# haltium_application register map
Vendor: Nordic Semiconductor; Series: nRFHaltium; File version: 1
CPU: CM33 r0p4, little endian, MPU, FPU, 3 interrupt priority bits, 480 interrupts
Registers are 32-bit, read-write, reset 0x0 unless marked. A register's access mark holds for its fields unless they carry their own. Offsets are from the block's base; [hi:lo] are bit positions; 'fields as' and 'values as' point back to an identical list.

## GLOBAL_SIMIF_NS — SIM card interface 0
Base 0x4F996000
Same registers: GLOBAL_SIMIF_S 0x5F996000
0x00 TASKS_DMASTARTRX wo — start DMA transfer from SIM card to memory
  [0] TASKS_DMASTARTRX
    1=Trigger task
0x04 TASKS_DMASTOPRX wo — stop DMA transfer from SIM card to memory
  [0] TASKS_DMASTOPRX
    1=Trigger task
0x08 TASKS_DMASTARTTX wo — start DMA transfer from memory to SIM card
  [0] TASKS_DMASTARTTX
    1=Trigger task
0x0C TASKS_DMASTOPTX wo — start DMA transfer from memory to SIM card
  [0] TASKS_DMASTOPTX
    1=Trigger task
0x10 TASKS_RSTSET wo — Set SIM card reset signal
  [0] TASKS_RSTSET
    1=Trigger task
0x14 TASKS_RSTCLEAR wo — Clear SIM card reset signal
  [0] TASKS_RSTCLEAR
    1=Trigger task
0x18 TASKS_RESET wo — Reset everything
  [0] TASKS_RESET
    1=Trigger task
0x1C TASKS_UARTRX wo — Start Uart for Rx access
  [0] TASKS_UARTRX
    1=Trigger task
0x20 TASKS_UARTTX wo — Start Uart for Tx access
  [0] TASKS_UARTTX
    1=Trigger task
0x24 TASKS_STARTWRITEFROMREG wo — Write test data from Ahb test reg to Ahb Rx bus
  [0] TASKS_STARTWRITEFROMREG
    1=Trigger task
0x28 TASKS_STARTREADTOREG wo — Read data from Ahb Tx bus to Ahb test reg
  [0] TASKS_STARTREADTOREG
    1=Trigger task
0x2C TASKS_PROTOCOLT0SET wo — Start using protocol T0
  [0] TASKS_PROTOCOLT0SET
    1=Trigger task
0x30 TASKS_PROTOCOLT1SET wo — Start using protocol T1
  [0] TASKS_PROTOCOLT1SET
    1=Trigger task
0x34 TASKS_PROTOCOLNONSET wo — Start using protocol none
  [0] TASKS_PROTOCOLNONSET
    1=Trigger task
0x38 TASKS_TIMECOUNTCLEAR wo — Stop and clear time out counter
  [0] TASKS_TIMECOUNTCLEAR
    1=Trigger task
0x100 EVENTS_DMA_RX_STARTED — DMA Rx operation started
  [0] EVENTS_DMA_RX_STARTED
    0=NotGenerated (Event not generated); 1=Generated (Event generated)
0x104 EVENTS_DMA_RX_DONE — DMA Tx operation finished
  [0] EVENTS_DMA_RX_DONE
    values as EVENTS_DMA_RX_STARTED.EVENTS_DMA_RX_STARTED
0x108 EVENTS_DMA_TX_STARTED — DMA Tx operation started
  [0] EVENTS_DMA_TX_STARTED
    values as EVENTS_DMA_RX_STARTED.EVENTS_DMA_RX_STARTED
0x10C EVENTS_DMA_TX_DONE — DMA Tx operation finished
  [0] EVENTS_DMA_TX_DONE
    values as EVENTS_DMA_RX_STARTED.EVENTS_DMA_RX_STARTED
0x110 EVENTS_INVALID_CONVENTION — ATR.TS convention not recognized
  [0] EVENTS_INVALID_CONVENTION
    values as EVENTS_DMA_RX_STARTED.EVENTS_DMA_RX_STARTED
0x114 EVENTS_PARITY_ERROR — Rx byte parity error
  [0] EVENTS_PARITY_ERROR
    values as EVENTS_DMA_RX_STARTED.EVENTS_DMA_RX_STARTED
0x118 EVENTS_ATR_TIMEOUT — No ATR between 400 and 40000 sim clock cycles
  [0] EVENTS_ATR_TIMEOUT
    values as EVENTS_DMA_RX_STARTED.EVENTS_DMA_RX_STARTED
0x11C EVENTS_CW_TIMEOUT — T=1 character wait timeout
  [0] EVENTS_CW_TIMEOUT
    values as EVENTS_DMA_RX_STARTED.EVENTS_DMA_RX_STARTED
0x120 EVENTS_BW_TIMEOUT — Block Wait timeout
  [0] EVENTS_BW_TIMEOUT
    values as EVENTS_DMA_RX_STARTED.EVENTS_DMA_RX_STARTED
0x124 EVENTS_SW1SW2 — SW1 and SW2 bytes received
  [0] EVENTS_SW1SW2
    values as EVENTS_DMA_RX_STARTED.EVENTS_DMA_RX_STARTED
0x128 EVENTS_RESET — Everything reset
  [0] EVENTS_RESET
    values as EVENTS_DMA_RX_STARTED.EVENTS_DMA_RX_STARTED
0x12C EVENTS_INS — T=0 procedure byte INS received
  [0] EVENTS_INS
    values as EVENTS_DMA_RX_STARTED.EVENTS_DMA_RX_STARTED
0x130 EVENTS_NINS — T=0 procedure byte !INS received
  [0] EVENTS_NINS
    values as EVENTS_DMA_RX_STARTED.EVENTS_DMA_RX_STARTED
0x134 EVENTS_ERROR — Error response
  [0] EVENTS_ERROR
    values as EVENTS_DMA_RX_STARTED.EVENTS_DMA_RX_STARTED
0x138 EVENTS_READY_TX — Byte sent after START_WRITE_FROM_REG
  [0] EVENTS_READY_TX
    values as EVENTS_DMA_RX_STARTED.EVENTS_DMA_RX_STARTED
0x13C EVENTS_RX_DATA_READY — Byte received after START_READ_TO_REG
  [0] EVENTS_RX_DATA_READY
    values as EVENTS_DMA_RX_STARTED.EVENTS_DMA_RX_STARTED
0x140 EVENTS_T1_RX_OVERRUN — Unexpected bytes received after DMA RX[0...N], SW1SW2 in T=1
  [0] EVENTS_T1_RX_OVERRUN
    values as EVENTS_DMA_RX_STARTED.EVENTS_DMA_RX_STARTED
0x144 EVENTS_T1_TX_ABORTED — T=1 card responded with S(ABORT request)
  [0] EVENTS_T1_TX_ABORTED
    values as EVENTS_DMA_RX_STARTED.EVENTS_DMA_RX_STARTED
0x148 EVENTS_T1_NON_I_BLOCK — T=1 unrecognized (S or R) block (with correct LRC) stored in RX_DATA
  [0] EVENTS_T1_NON_I_BLOCK
    values as EVENTS_DMA_RX_STARTED.EVENTS_DMA_RX_STARTED
0x14C EVENTS_T1_LEN_ERROR — T=1 LEN = 255
  [0] EVENTS_T1_LEN_ERROR
    values as EVENTS_DMA_RX_STARTED.EVENTS_DMA_RX_STARTED
0x150 EVENTS_EDC_ERROR — T=1 EDC error
  [0] EVENTS_EDC_ERROR
    values as EVENTS_DMA_RX_STARTED.EVENTS_DMA_RX_STARTED
0x154 EVENTS_NAD_ERROR — T=1 NAD error
  [0] EVENTS_NAD_ERROR
    values as EVENTS_DMA_RX_STARTED.EVENTS_DMA_RX_STARTED
0x158 EVENTS_EVENTS_ERROR_COUNT_MAX — number of unsuccessful rx or tx operations equals max value
  [0] EVENTS_EVENTS_ERROR_COUNT_MAX
    values as EVENTS_DMA_RX_STARTED.EVENTS_DMA_RX_STARTED
0x15C EVENTS_EVENTS_T1_RX_MORE — More bit high in PCB of Rx T=1 I block
  [0] EVENTS_EVENTS_T1_RX_MORE
    values as EVENTS_DMA_RX_STARTED.EVENTS_DMA_RX_STARTED
0x160 EVENTS_EVENTS_T1_RX_FRAME_END — Len byte + 1 bytes of T1 Rx data received
  [0] EVENTS_EVENTS_T1_RX_FRAME_END
    values as EVENTS_DMA_RX_STARTED.EVENTS_DMA_RX_STARTED
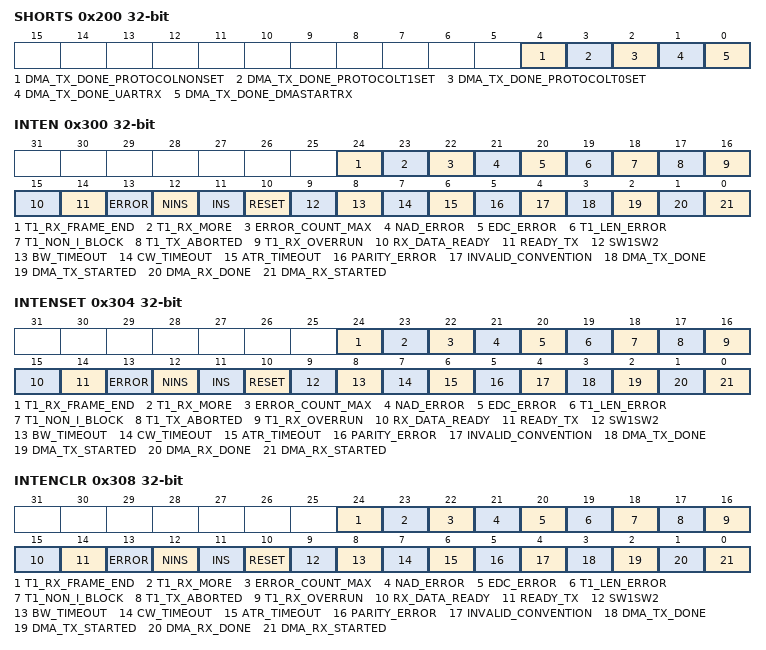
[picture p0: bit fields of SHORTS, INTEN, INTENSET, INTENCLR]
0x200 SHORTS — Shortcuts between local events and tasks
  [all] fields
    0=Disabled (Disable shortcut); 1=Enabled (Enable shortcut)
  [4] DMA_TX_DONE_PROTOCOLNONSET — Shortcut between event DMA_TX_DONE and task PROTOCOLNONSET
  [3] DMA_TX_DONE_PROTOCOLT1SET — Shortcut between event DMA_TX_DONE and task PROTOCOLT1SET
  [2] DMA_TX_DONE_PROTOCOLT0SET — Shortcut between event DMA_TX_DONE and task PROTOCOLT0SET
  [1] DMA_TX_DONE_UARTRX — Shortcut between event DMA_TX_DONE and task UARTRX
  [0] DMA_TX_DONE_DMASTARTRX — Shortcut between event DMA_TX_DONE and task DMASTARTRX
0x300 INTEN — Enable or disable interrupt
  [all] fields
    0=Disabled; 1=Enabled
  [24] T1_RX_FRAME_END — Enable or disable interrupt for event T1_RX_FRAME_END
  [23] T1_RX_MORE — Enable or disable interrupt for event T1_RX_MORE
  [22] ERROR_COUNT_MAX — Enable or disable interrupt for event ERROR_COUNT_MAX
  [21] NAD_ERROR — Enable or disable interrupt for event NAD_ERROR
  [20] EDC_ERROR — Enable or disable interrupt for event EDC_ERROR
  [19] T1_LEN_ERROR — Enable or disable interrupt for event T1_LEN_ERROR
  [18] T1_NON_I_BLOCK — Enable or disable interrupt for event T1_NON_I_BLOCK
  [17] T1_TX_ABORTED — Enable or disable interrupt for event T1_TX_ABORTED
  [16] T1_RX_OVERRUN — Enable or disable interrupt for event T1_RX_OVERRUN
  [15] RX_DATA_READY — Enable or disable interrupt for event RX_DATA_READY
  [14] READY_TX — Enable or disable interrupt for event READY_TX
  [13] ERROR — Enable or disable interrupt for event ERROR
  [12] NINS — Enable or disable interrupt for event NINS
  [11] INS — Enable or disable interrupt for event INS
  [10] RESET — Enable or disable interrupt for event RESET
  [9] SW1SW2 — Enable or disable interrupt for event SW1SW2
  [8] BW_TIMEOUT — Enable or disable interrupt for event BW_TIMEOUT
  [7] CW_TIMEOUT — Enable or disable interrupt for event CW_TIMEOUT
  [6] ATR_TIMEOUT — Enable or disable interrupt for event ATR_TIMEOUT
  [5] PARITY_ERROR — Enable or disable interrupt for event PARITY_ERROR
  [4] INVALID_CONVENTION — Enable or disable interrupt for event INVALID_CONVENTION
  [3] DMA_TX_DONE — Enable or disable interrupt for event DMA_TX_DONE
  [2] DMA_TX_STARTED — Enable or disable interrupt for event DMA_TX_STARTED
  [1] DMA_RX_DONE — Enable or disable interrupt for event DMA_RX_DONE
  [0] DMA_RX_STARTED — Enable or disable interrupt for event DMA_RX_STARTED
0x304 INTENSET — Enable interrupt
  [all] fields
    on read: 0=Disabled (Read: Disabled); 1=Enabled (Read: Enabled) | on write: 1=Set (Enable)
  [24] T1_RX_FRAME_END — Write '1' to enable interrupt for event T1_RX_FRAME_END
  [23] T1_RX_MORE — Write '1' to enable interrupt for event T1_RX_MORE
  [22] ERROR_COUNT_MAX — Write '1' to enable interrupt for event ERROR_COUNT_MAX
  [21] NAD_ERROR — Write '1' to enable interrupt for event NAD_ERROR
  [20] EDC_ERROR — Write '1' to enable interrupt for event EDC_ERROR
  [19] T1_LEN_ERROR — Write '1' to enable interrupt for event T1_LEN_ERROR
  [18] T1_NON_I_BLOCK — Write '1' to enable interrupt for event T1_NON_I_BLOCK
  [17] T1_TX_ABORTED — Write '1' to enable interrupt for event T1_TX_ABORTED
  [16] T1_RX_OVERRUN — Write '1' to enable interrupt for event T1_RX_OVERRUN
  [15] RX_DATA_READY — Write '1' to enable interrupt for event RX_DATA_READY
  [14] READY_TX — Write '1' to enable interrupt for event READY_TX
  [13] ERROR — Write '1' to enable interrupt for event ERROR
  [12] NINS — Write '1' to enable interrupt for event NINS
  [11] INS — Write '1' to enable interrupt for event INS
  [10] RESET — Write '1' to enable interrupt for event RESET
  [9] SW1SW2 — Write '1' to enable interrupt for event SW1SW2
  [8] BW_TIMEOUT — Write '1' to enable interrupt for event BW_TIMEOUT
  [7] CW_TIMEOUT — Write '1' to enable interrupt for event CW_TIMEOUT
  [6] ATR_TIMEOUT — Write '1' to enable interrupt for event ATR_TIMEOUT
  [5] PARITY_ERROR — Write '1' to enable interrupt for event PARITY_ERROR
  [4] INVALID_CONVENTION — Write '1' to enable interrupt for event INVALID_CONVENTION
  [3] DMA_TX_DONE — Write '1' to enable interrupt for event DMA_TX_DONE
  [2] DMA_TX_STARTED — Write '1' to enable interrupt for event DMA_TX_STARTED
  [1] DMA_RX_DONE — Write '1' to enable interrupt for event DMA_RX_DONE
  [0] DMA_RX_STARTED — Write '1' to enable interrupt for event DMA_RX_STARTED
0x308 INTENCLR — Disable interrupt
  [all] fields
    on read: 0=Disabled (Read: Disabled); 1=Enabled (Read: Enabled) | on write: 1=Clear (Disable)
  [24] T1_RX_FRAME_END — Write '1' to disable interrupt for event T1_RX_FRAME_END
  [23] T1_RX_MORE — Write '1' to disable interrupt for event T1_RX_MORE
  [22] ERROR_COUNT_MAX — Write '1' to disable interrupt for event ERROR_COUNT_MAX
  [21] NAD_ERROR — Write '1' to disable interrupt for event NAD_ERROR
  [20] EDC_ERROR — Write '1' to disable interrupt for event EDC_ERROR
  [19] T1_LEN_ERROR — Write '1' to disable interrupt for event T1_LEN_ERROR
  [18] T1_NON_I_BLOCK — Write '1' to disable interrupt for event T1_NON_I_BLOCK
  [17] T1_TX_ABORTED — Write '1' to disable interrupt for event T1_TX_ABORTED
  [16] T1_RX_OVERRUN — Write '1' to disable interrupt for event T1_RX_OVERRUN
  [15] RX_DATA_READY — Write '1' to disable interrupt for event RX_DATA_READY
  [14] READY_TX — Write '1' to disable interrupt for event READY_TX
  [13] ERROR — Write '1' to disable interrupt for event ERROR
  [12] NINS — Write '1' to disable interrupt for event NINS
  [11] INS — Write '1' to disable interrupt for event INS
  [10] RESET — Write '1' to disable interrupt for event RESET
  [9] SW1SW2 — Write '1' to disable interrupt for event SW1SW2
  [8] BW_TIMEOUT — Write '1' to disable interrupt for event BW_TIMEOUT
  [7] CW_TIMEOUT — Write '1' to disable interrupt for event CW_TIMEOUT
  [6] ATR_TIMEOUT — Write '1' to disable interrupt for event ATR_TIMEOUT
  [5] PARITY_ERROR — Write '1' to disable interrupt for event PARITY_ERROR
  [4] INVALID_CONVENTION — Write '1' to disable interrupt for event INVALID_CONVENTION
  [3] DMA_TX_DONE — Write '1' to disable interrupt for event DMA_TX_DONE
  [2] DMA_TX_STARTED — Write '1' to disable interrupt for event DMA_TX_STARTED
  [1] DMA_RX_DONE — Write '1' to disable interrupt for event DMA_RX_DONE
  [0] DMA_RX_STARTED — Write '1' to disable interrupt for event DMA_RX_STARTED
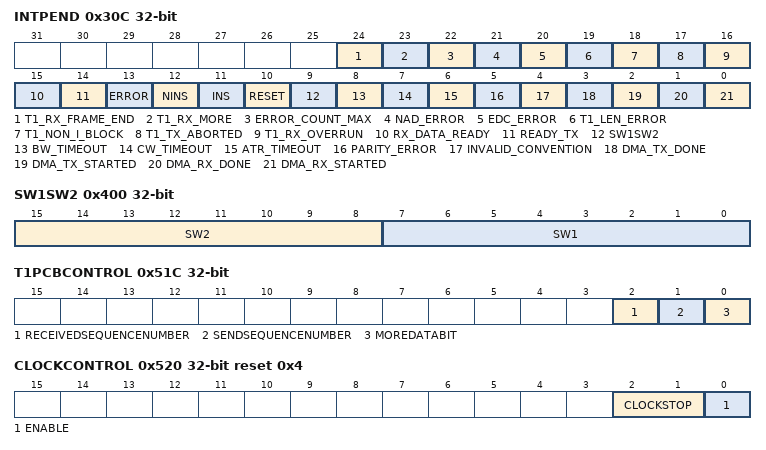
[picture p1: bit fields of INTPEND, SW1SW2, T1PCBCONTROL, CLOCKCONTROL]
0x30C INTPEND ro — Pending interrupts
  [all] fields
    on read: 0=NotPending (Read: Not pending); 1=Pending (Read: Pending)
  [24] T1_RX_FRAME_END — Read pending status of interrupt for event T1_RX_FRAME_END
  [23] T1_RX_MORE — Read pending status of interrupt for event T1_RX_MORE
  [22] ERROR_COUNT_MAX — Read pending status of interrupt for event ERROR_COUNT_MAX
  [21] NAD_ERROR — Read pending status of interrupt for event NAD_ERROR
  [20] EDC_ERROR — Read pending status of interrupt for event EDC_ERROR
  [19] T1_LEN_ERROR — Read pending status of interrupt for event T1_LEN_ERROR
  [18] T1_NON_I_BLOCK — Read pending status of interrupt for event T1_NON_I_BLOCK
  [17] T1_TX_ABORTED — Read pending status of interrupt for event T1_TX_ABORTED
  [16] T1_RX_OVERRUN — Read pending status of interrupt for event T1_RX_OVERRUN
  [15] RX_DATA_READY — Read pending status of interrupt for event RX_DATA_READY
  [14] READY_TX — Read pending status of interrupt for event READY_TX
  [13] ERROR — Read pending status of interrupt for event ERROR
  [12] NINS — Read pending status of interrupt for event NINS
  [11] INS — Read pending status of interrupt for event INS
  [10] RESET — Read pending status of interrupt for event RESET
  [9] SW1SW2 — Read pending status of interrupt for event SW1SW2
  [8] BW_TIMEOUT — Read pending status of interrupt for event BW_TIMEOUT
  [7] CW_TIMEOUT — Read pending status of interrupt for event CW_TIMEOUT
  [6] ATR_TIMEOUT — Read pending status of interrupt for event ATR_TIMEOUT
  [5] PARITY_ERROR — Read pending status of interrupt for event PARITY_ERROR
  [4] INVALID_CONVENTION — Read pending status of interrupt for event INVALID_CONVENTION
  [3] DMA_TX_DONE — Read pending status of interrupt for event DMA_TX_DONE
  [2] DMA_TX_STARTED — Read pending status of interrupt for event DMA_TX_STARTED
  [1] DMA_RX_DONE — Read pending status of interrupt for event DMA_RX_DONE
  [0] DMA_RX_STARTED — Read pending status of interrupt for event DMA_RX_STARTED
0x400 SW1SW2 — Sw1 and Sw2 bytes received from Sim card in T=1 mode
  [15:8] SW2 — Sw2 data byte received
  [7:0] SW1 — Sw1 data byte received
0x404 CONVENTION — Data convention used in traffic between controller and SIM card
  [0] DATACONVENTION — Data convention between controller and SIM card
    0=Direct convention: 1 = High, LSB first; 1=Inverse convention: 1 = Low, MSB first
0x408 LRCOUT — Latest generated LRC value
  [7:0] LRCOUT
0x40C RXDATA ro — NonDMA received data
  [7:0] RXDATA — NonDMA received data or Rx data of T=1 S block if RxBufferLength = 3
0x410 T0SWXCOUNT — Number of SWx bytes received after T=0 Rx DMA finished
  [1:0] T0SWXCOUNT
0x500 CLKRATE reset 0x18 — Divider value for setting the clock rate to the SIM card.
  [9:0] CLOCKRATE — Divider for setting the clock frequency to the SIM card clock (clock = input clock / ClockRate
0x504 BAUDRATE reset 0x174 — Divider value for setting the baud rate to the SIM card.
  [9:0] BAUDRATE — Divider for setting the baud rate to the SIM card.(Baud rate = Sim card clock/BaudRate).
0x508 CHARACTERGUARDTIME reset 0xC
  [31:0] CHARACTERGUARDTIME — Guard time from leading edge of the character to the leading edge of the next character in ETU
0x50C CHARACTERWAITTIME reset 0xD
  [31:0] CHARACTERWAITTIME — T=1 character Rx wait time in ETU
0x510 BLOCKWAITTIME reset 0x2580
  [31:0] BLOCKWAITTIME — Block wait time in ETU, default 9600
0x514 PROTOCOL — Protocol selection
  [0] PROTOCOL — Protocol selection 0: T=0, 1: T=1
    0=T0; 1=T1
0x518 LOWIMPEDANCE — Low impedance driver use
  [0] LOWIMPEDANCE
    0=OpenDrain; 1=LowImpedance (use low impedance drivers)
0x51C T1PCBCONTROL — T=1 Tx PCB bits 5:6
  [2] RECEIVEDSEQUENCENUMBER ro — Rx Send Sequence number in T1 I Block
  [1] SENDSEQUENCENUMBER — Send Sequence number, PCB[6]
  [0] MOREDATABIT — More data (chaining) bit, PCB[5]
0x520 CLOCKCONTROL reset 0x4
  [2:1] CLOCKSTOP — Clock stop state
    0=Illegal (Not allowed); 1=High (Clock stops low); 2=Low (Clock stops high)
  [0] ENABLE — Enable clock
    0=ClockOff (Clock is off); 1=ClockOn (Clock is on)
0x524 VOLTAGE reset 0x1 — Sim card operating voltage
  [1:0] VOLTAGE
    0=0V (Card voltage off); 1=1800mV (Card operating voltage 1.8V); 2=3000mV (Card operating voltage 3V)
0x528 LRCENABLE — LRC Calculation enable
  [0] LRCENABLE — LRC Calculation enable for T=1
    0=Disable (LRC calculation disabled); 1=Enable (LRC calculation enabled)
0x52C TXDATA wo — NonDMA data to be sent to the SIM card
  [7:0] TXDATA
0x530 UARTCONFIG — Uart configuration
  [2:0] UARTCONFIG — Uart configuration, for details see Uart spec
0x534 WRITEMAXATT reset 0xA — Number of write attempts before error interrupt
  [7:0] WRITEMAXATT
0x538 READMAXATT reset 0xA — Number of read attempts before error interrupt
  [7:0] READMAXATT
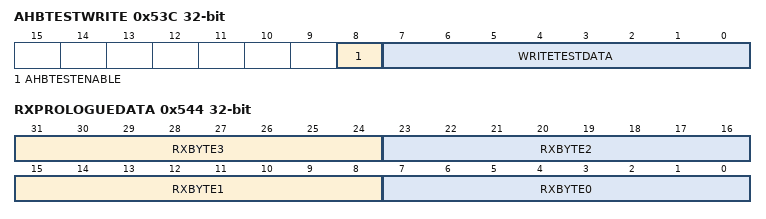
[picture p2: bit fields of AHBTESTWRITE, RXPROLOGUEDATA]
0x53C AHBTESTWRITE — Test data to write through AHB RX bus
  [8] AHBTESTENABLE — Enable bit for Ahb testing, both read and write
  [7:0] WRITETESTDATA — Test data for Ahb write access for Ahb Rx bus
0x540 AHBTESTREAD ro — Test data to read through AHB TX bus
  [7:0] READTESTDATA — Test data read through Ahb Tx bus
0x544 RXPROLOGUEDATA — Four first Rx data bytes from card
  [31:24] RXBYTE3 — Fourth Rx byte from card
  [23:16] RXBYTE2 — Third Rx byte from card
  [15:8] RXBYTE1 — Second Rx byte from card
  [7:0] RXBYTE0 — First Rx byte from card
0x574 UARTENABLE
  [0] ENABLE — UART master enable
0x578 UARTRXENABLE wo
  [0] ENABLE — UART Rx enable
0x57C UARTTXENABLE wo
  [0] ENABLE — UART Tx enable
0x600 DMARXADDR — DMA access buffer RAM start address
  [31:0] DMARXSTARTADDRESS
0x604 DMARXBUFFERSIZE — Byte count to receive in Dma Rx operation
  [15:0] DMARXBUFFERSIZE
0x608 DMARXBYTECOUNT ro — Byte count received in latest Dma Rx operation
  [15:0] DMARXBYTECOUNT
0x60C DMARXENABLE — Enable for rx dma
  [0] DMARXENABLE
0x610 DMARXSELECTLIST ro — Rx select address from list
  [1:0] DMARXSELECTLIST — Select address from list
0x700 DMATXADDR — Start address for DMA access in buffer RAM
  [31:0] DMATXSTARTADDRESS
0x704 DMATXBUFFERSIZE — Byte count to transmit in Dma Rx operation
  [15:0] DMATXBUFFERSIZE — Byte count to transmit in Dma Tx operation
0x708 DMATXBYTECOUNT ro — Byte count transmitted in latest Dma Tx operation
  [15:0] DMATXBYTECOUNT
0x70C DMATXENABLE — Enable for rx dma
  [0] DMATXENABLE
0x710 DMATXSELECTLIST ro — Tx select address from list
  [1:0] DMATXSELECTLIST — Select address from list
